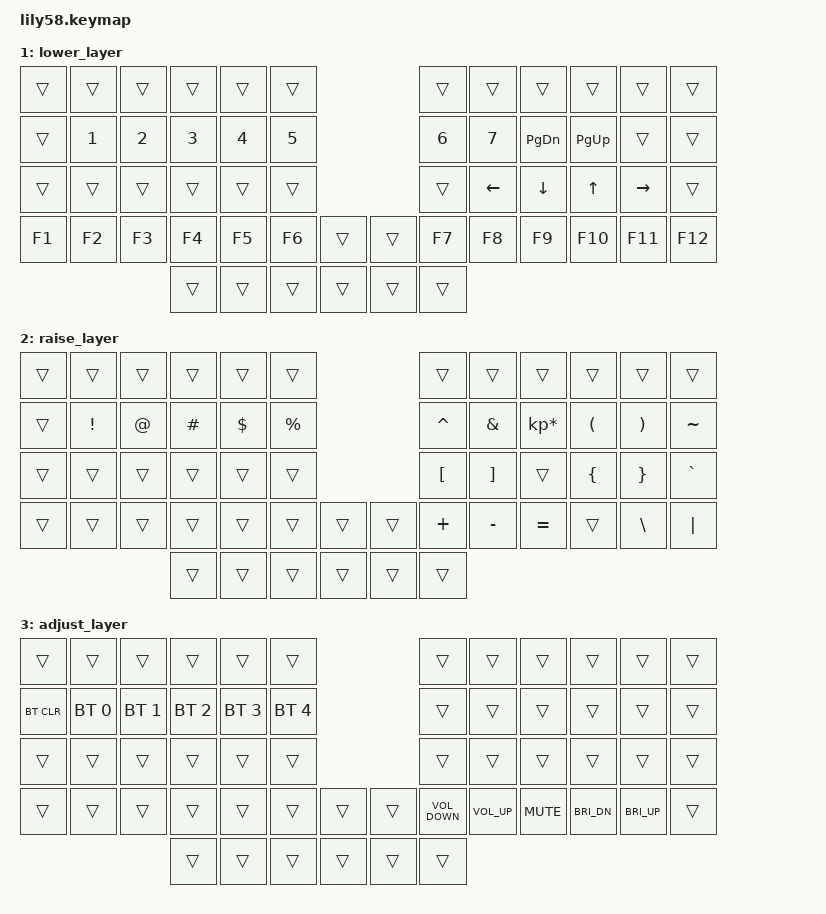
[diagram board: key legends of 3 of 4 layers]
#include <behaviors.dtsi>
#include <dt-bindings/zmk/bt.h>
#include <dt-bindings/zmk/keys.h>

/ {
    combos {
        compatible = "zmk,combos";

        d_shift_caps_word {
            bindings = <&d_shift_caps_word>;
            key-positions = <36 49>;
        };
    };

    behaviors {
        d_shift_caps_word: d_shift_caps_word {
            compatible = "zmk,behavior-caps-word";
            label = "D_SHIFT_CAPS_WORD";
            #binding-cells = <0>;
            mods = <(MOD_LSFT)>;
            continue-list = <BACKSPACE UNDERSCORE SPACE RIGHT_ARROW LEFT_ARROW>;
        };

        hmr_l: hmr_l {
            compatible = "zmk,behavior-hold-tap";
            label = "HMR_L";
            bindings = <&kp>, <&kp>;

            #binding-cells = <2>;
            tapping-term-ms = <300>;
            quick-tap-ms = <175>;
            flavor = "balanced";
            hold-trigger-key-positions = <54 55 56 57 43 44 45 6 7 8 9 10 11 18 19 20 21 22 23 30 31 32 33 34 35 44 45 46 47 48 49 53 51 50>;
            hold-trigger-on-release;
        };

        hmr_r: hmr_r {
            compatible = "zmk,behavior-hold-tap";
            label = "HMR_R";
            bindings = <&kp>, <&kp>;

            #binding-cells = <2>;
            tapping-term-ms = <300>;
            quick-tap-ms = <175>;
            flavor = "balanced";
            hold-trigger-on-release;
            hold-trigger-key-positions = <54 56 57 0 1 2 3 4 5 12 13 14 15 16 17 24 25 26 27 28 29 36 37 38 39 40 41 42 50 51 52 53>;
        };
    };

    keymap {
        compatible = "zmk,keymap";

        default_layer {
            // ------------------------------------------------------------------------------------------------------------
            // |  ESC  |  1  |  2  |  3   |  4   |  5   |                   |  6   |  7    |  8    |  9   |   0   |   `   |
            // |  TAB  |  Q  |  W  |  E   |  R   |  T   |                   |  Y   |  U    |  I    |  O   |   P   |   -   |
            // |  CTRL |  A  |  S  |  D   |  F   |  G   |                   |  H   |  J    |  K    |  L   |   ;   |   '   |
            // | SHIFT |  Z  |  X  |  C   |  V   |  B   |   "["  |  |  "]"  |  N   |  M    |  ,    |  .   |   /   | SHIFT |
            //                     | ALT  | GUI  | RAISE|  SPACE |  | ENTER | LOWER| BSPC  | GUI   |

            bindings = <
&kp ESC     &kp N1  &kp N2          &kp N3             &kp N4    &kp N5                         &kp N6  &kp N7    &kp N8              &kp N9          &kp N0                   &kp GRAVE
&kp ESCAPE  &kp Q   &kp W           &kp E              &kp R     &kp T                          &kp Y   &kp U     &kp I               &kp O           &kp P                    &kp MINUS
&kp TAB     &kp A   &hmr_l LCTRL S  &hmr_l LEFT_ALT D  &kp F     &kp G                          &kp H   &kp J     &hmr_r RIGHT_ALT K  &hmr_r RCTRL L  &hmr_r RIGHT_SHIFT SEMI  &kp SQT
&kp LSHFT   &kp Z   &kp X           &kp C              &kp V     &kp B   &kp LBKT     &kp RBKT  &kp N   &kp M     &kp COMMA           &kp DOT         &kp FSLH                 &kp RSHFT
                                    &kp LALT           &kp LGUI  &mo 2   &kp SPACE    &kp RET   &mo 1   &kp BSPC  &kp RGUI
            >;
        };

        lower_layer {
            bindings = <
&trans  &trans  &trans  &trans  &trans  &trans                    &trans  &trans          &trans          &trans        &trans           &trans
&trans  &kp N1  &kp N2  &kp N3  &kp N4  &kp N5                    &kp N6  &kp N7          &kp PAGE_DOWN   &kp PAGE_UP   &trans           &trans
&trans  &trans  &trans  &trans  &trans  &trans                    &trans  &kp LEFT_ARROW  &kp DOWN_ARROW  &kp UP_ARROW  &kp RIGHT_ARROW  &trans
&kp F1  &kp F2  &kp F3  &kp F4  &kp F5  &kp F6  &trans    &trans  &kp F7  &kp F8          &kp F9          &kp F10       &kp F11          &kp F12
                        &trans  &trans  &trans  &trans    &trans  &trans
            >;
        };

        raise_layer {
            bindings = <
&trans  &trans    &trans  &trans    &trans    &trans                       &trans            &trans             &trans           &trans          &trans           &trans
&trans  &kp EXCL  &kp AT  &kp HASH  &kp DLLR  &kp PRCNT                    &kp CARET         &kp AMPS           &kp KP_MULTIPLY  &kp LPAR        &kp RPAR         &kp TILDE
&trans  &trans    &trans  &trans    &trans    &trans                       &kp LEFT_BRACKET  &kp RIGHT_BRACKET  &trans           &kp LEFT_BRACE  &kp RIGHT_BRACE  &kp GRAVE
&trans  &trans    &trans  &trans    &trans    &trans     &trans    &trans  &kp PLUS          &kp MINUS          &kp EQUAL        &trans          &kp BACKSLASH    &kp PIPE
                          &trans    &trans    &trans     &trans    &trans  &trans
            >;
        };

        adjust_layer {
            bindings = <
&trans      &trans        &trans        &trans        &trans        &trans                          &trans             &trans        &trans      &trans        &trans        &trans
&bt BT_CLR  &bt BT_SEL 0  &bt BT_SEL 1  &bt BT_SEL 2  &bt BT_SEL 3  &bt BT_SEL 4                    &trans             &trans        &trans      &trans        &trans        &trans
&trans      &trans        &trans        &trans        &trans        &trans                          &trans             &trans        &trans      &trans        &trans        &trans
&trans      &trans        &trans        &trans        &trans        &trans        &trans    &trans  &kp C_VOLUME_DOWN  &kp C_VOL_UP  &kp K_MUTE  &kp C_BRI_DN  &kp C_BRI_UP  &trans
                                        &trans        &trans        &trans        &trans    &trans  &trans
            >;
        };
    };

    conditional_layers {
        compatible = "zmk,conditional-layers";

        adjust_layer {
            if-layers = <1 2>;
            then-layer = <3>;
        };
    };
};
